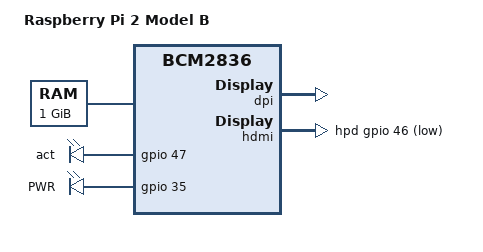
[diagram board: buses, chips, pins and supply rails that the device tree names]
/dts-v1/;
#include "bcm2836.dtsi"
#include "bcm2835-rpi.dtsi"

/ {
	compatible = "raspberrypi,2-model-b", "brcm,bcm2836";
	model = "Raspberry Pi 2 Model B";

	memory {
		reg = <0 0x40000000>;
	};

	leds {
		act {
			gpios = <&gpio 47 0>;
		};

		pwr {
			label = "PWR";
			gpios = <&gpio 35 0>;
			default-state = "keep";
			linux,default-trigger = "default-on";
		};
	};
};

&gpio {
	pinctrl-0 = <&alt0 &alt3>;

	/* I2S interface */
	i2s_alt0: i2s_alt0 {
		brcm,pins = <18 19 20 21>;
		brcm,function = <BCM2835_FSEL_ALT0>;
	};

	dpi_pins: dpi_pins {
		brcm,pins = <0 1 2 3 4 5 6 7 8 9 10 11 12 13 14 15 16 17 18 19 20 21 22 23>;
		brcm,function = <BCM2835_FSEL_ALT2>;
	};
};

&dpi {
	pinctrl-names = "default";
	pinctrl-0 = <&dpi_pins>;
	status = "okay";
};

&hdmi {
	hpd-gpios = <&gpio 46 GPIO_ACTIVE_LOW>;
};
